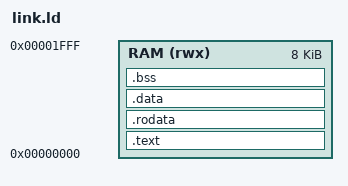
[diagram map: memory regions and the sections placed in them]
/* C programs: 8 KiB RAM at 0 (the Basys3 memory size; the simulation RAM is larger).
   Code, data and stack share it; the stack starts at the top and grows down. */
OUTPUT_ARCH("riscv")
ENTRY(_start)

MEMORY
{
  RAM (rwx) : ORIGIN = 0x00000000, LENGTH = 8K
}

SECTIONS
{
  .text   : { *(.text.init) *(.text .text.*) } > RAM
  .rodata : { *(.rodata .rodata.* .srodata .srodata.*) } > RAM
  .data   : {
    *(.data .data.*)
    __global_pointer$ = . + 0x800;
    *(.sdata .sdata.*)
  } > RAM
  .bss    : {
    __bss_start = .;
    *(.sbss .sbss.* .bss .bss.* COMMON)
    . = ALIGN(4);
    __bss_end = .;
  } > RAM
  __stack_top = ORIGIN(RAM) + LENGTH(RAM);
}
